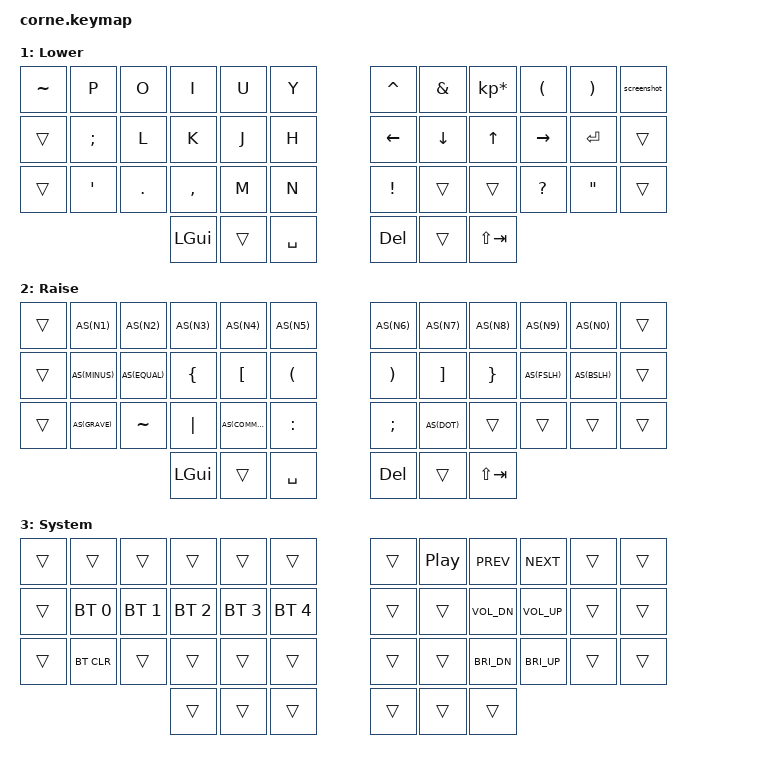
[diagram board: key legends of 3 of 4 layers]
/*
 * Copyright (c) 2020 The ZMK Contributors
 *
 * SPDX-License-Identifier: MIT
 */

#include <behaviors.dtsi>
#include <dt-bindings/zmk/keys.h>
#include <dt-bindings/zmk/bt.h>

#define AS(keycode) &as LS(keycode) keycode

// Simplified homerow mods for Mac (CTRL-ALT-GUI order, no shift)
#define HRML(k1,k2,k3)  &ht LCTRL k1 &ht LALT k2 &ht LGUI k3
#define HRMR(k1,k2,k3)  &ht LGUI k1 &ht LALT k2 &ht LCTRL k3

#define BASE 0
#define LOWER 1
#define RAISE 2
#define TRI 3

/ {
    behaviors {
        as: auto_shift {
            compatible = "zmk,behavior-hold-tap";
            #binding-cells = <2>;
            tapping_term_ms = <185>;
            quick_tap_ms = <150>;
            require-prior-idle-ms = <125>;
            flavor = "balanced";
            bindings = <&kp>, <&kp>;
        };

         ht: hold_tap {
            label = "hold_tap";
            compatible = "zmk,behavior-hold-tap";
            #binding-cells = <2>;
            flavor = "balanced";
            tapping-term-ms = <200>;
            quick-tap-ms = <150>;
            require-prior-idle-ms = <125>;
            global-quick-tap;
            bindings = <&kp>, <&kp>;
        };

        conditional_layers {
            compatible = "zmk,conditional-layers";
            tri_layer {
                if-layers = <LOWER RAISE>;
                then-layer = <TRI>;
            };
        };
    };

    macros {
        screenshot: screenshot {
            label = "screenshot";
            compatible = "zmk,behavior-macro";
            #binding-cells = <0>;
            wait-ms = <0>;
            tap-ms = <0>;
            bindings = <&macro_press &kp LCMD &kp LSHFT>
                     , <&macro_tap &kp N4>
                     , <&macro_release &kp LCMD &kp LSHFT>;
        };
    };
    
    keymap {
        compatible = "zmk,keymap";

        default_layer {
            display-name = "Base";
            bindings = <
// ┌────────┬────────┬────────┬────────┬────────┬────────┐   ┌────────┬────────┬────────┬────────┬────────┬────────┐
    &kp ESC   &kp Q    &kp W    &kp E    &kp R    &kp T       &kp Y    &kp U    &kp I    &kp O    &kp P    &kp BSPC
// ├────────┼────────┼────────┼────────┼────────┼────────┤   ├────────┼────────┼────────┼────────┼────────┼────────┤
    &kp LCMD  HRML(A,      S,       D)   &kp F    &kp G       &kp H    &kp J    HRMR(K,      L,     SEMI)  &kp FSLH
// ├────────┼────────┼────────┼────────┼────────┼────────┤   ├────────┼────────┼────────┼────────┼────────┼────────┤
    &kp LSHFT &kp Z    &kp X    &ht LG(C) C &ht LG(V) V &kp B    &kp N  &kp M &kp COMMA  &kp DOT   &kp SQT &kp RSHFT
// └────────┴────────┴────────┼────────┼────────┼────────┤   ├────────┼────────┼────────┼────────┴────────┴────────┘
                               &ht LC(LS(LALT)) ESC &mo LOWER &kp SPACE   &kp BSPC &mo RAISE &kp TAB
//                           └────────┴────────┴────────┘   └────────┴────────┴────────┘
            >;
        };

        lower_layer {
            display-name = "Lower";
            bindings = <
// ┌────────┬────────┬────────┬────────┬────────┬────────┐   ┌────────┬────────┬────────┬────────┬────────┬────────┐
    &kp TILDE &kp P    &kp O    &kp I    &kp U    &kp Y       &kp CARET &kp AMPS &kp KP_MULTIPLY &kp LPAR &kp RPAR &screenshot
// ├────────┼────────┼────────┼────────┼────────┼────────┤   ├────────┼────────┼────────┼────────┼────────┼────────┤
    &trans    &kp SEMI &kp L    &kp K    &kp J    &kp H       &kp LEFT &kp DOWN &kp UP   &kp RIGHT &kp RET  &trans
// ├────────┼────────┼────────┼────────┼────────┼────────┤   ├────────┼────────┼────────┼────────┼────────┼────────┤
    &trans    &kp SQT  &kp DOT  &kp COMMA &kp M   &kp N       &kp EXCL &trans   &trans   &kp QMARK &kp DQT &trans
// └────────┴────────┴────────┼────────┼────────┼────────┤   ├────────┼────────┼────────┼────────┴────────┴────────┘
                               &kp LGUI &trans   &kp SPACE   &kp DEL  &trans   &kp LS(TAB)
//                           └────────┴────────┴────────┘   └────────┴────────┴────────┘
            >;
        };

        raise_layer {
            display-name = "Raise";
            bindings = <
// ┌────────┬────────┬────────┬────────┬────────┬────────┐   ┌────────┬────────┬────────┬────────┬────────┬────────┐
    &trans    AS(N1)   AS(N2)   AS(N3)   AS(N4)   AS(N5)      AS(N6)   AS(N7)   AS(N8)   AS(N9)   AS(N0)   &trans
// ├────────┼────────┼────────┼────────┼────────┼────────┤   ├────────┼────────┼────────┼────────┼────────┼────────┤
    &trans    AS(MINUS) AS(EQUAL) &kp LBRC &kp LBKT &kp LPAR   &kp RPAR &kp RBKT &kp RBRC AS(FSLH) AS(BSLH) &trans
// ├────────┼────────┼────────┼────────┼────────┼────────┤   ├────────┼────────┼────────┼────────┼────────┼────────┤
    &trans    AS(GRAVE) &kp TILDE &kp PIPE AS(COMMA) &kp COLON &kp SEMI AS(DOT)  &trans   &trans   &trans   &trans
// └────────┴────────┴────────┼────────┼────────┼────────┤   ├────────┼────────┼────────┼────────┴────────┴────────┘
                               &kp LGUI &trans   &kp SPACE   &kp DEL  &trans   &kp LS(TAB)
//                           └────────┴────────┴────────┘   └────────┴────────┴────────┘
            >;
        };

        tri_layer {
            display-name = "System";
            bindings = <
// ┌────────┬────────┬────────┬────────┬────────┬────────┐   ┌────────┬────────┬────────┬────────┬────────┬────────┐
    &trans    &trans   &trans   &trans   &trans   &trans      &trans   &kp C_PP &kp C_PREV &kp C_NEXT &trans &trans
// ├────────┼────────┼────────┼────────┼────────┼────────┤   ├────────┼────────┼────────┼────────┼────────┼────────┤
    &trans    &bt BT_SEL 0 &bt BT_SEL 1 &bt BT_SEL 2 &bt BT_SEL 3 &bt BT_SEL 4 &trans &trans &kp C_VOL_DN &kp C_VOL_UP &trans &trans
// ├────────┼────────┼────────┼────────┼────────┼────────┤   ├────────┼────────┼────────┼────────┼────────┼────────┤
    &trans    &bt BT_CLR &trans  &trans   &trans   &trans      &trans   &trans   &kp C_BRI_DN &kp C_BRI_UP &trans &trans
// └────────┴────────┴────────┼────────┼────────┼────────┤   ├────────┼────────┼────────┼────────┴────────┴────────┘
                               &trans   &trans   &trans      &trans   &trans   &trans
//                           └────────┴────────┴────────┘   └────────┴────────┴────────┘
            >;
        };
    };
};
